# TM4C123GH6PM register map
Vendor: Texas Instruments; Series: TM4C; File version: 11073
CPU: CM4 r1p2, little endian, MPU, FPU, 3 interrupt priority bits
Registers are 32-bit, read-write, reset 0x1 unless marked. A register's access mark holds for its fields unless they carry their own. Offsets are from the block's base; [hi:lo] are bit positions; {n}, {i} and the like mark numbered series.

## UDMA — Register map for UDMA peripheral
Base 0x400FF000; register names take the prefix UDMA
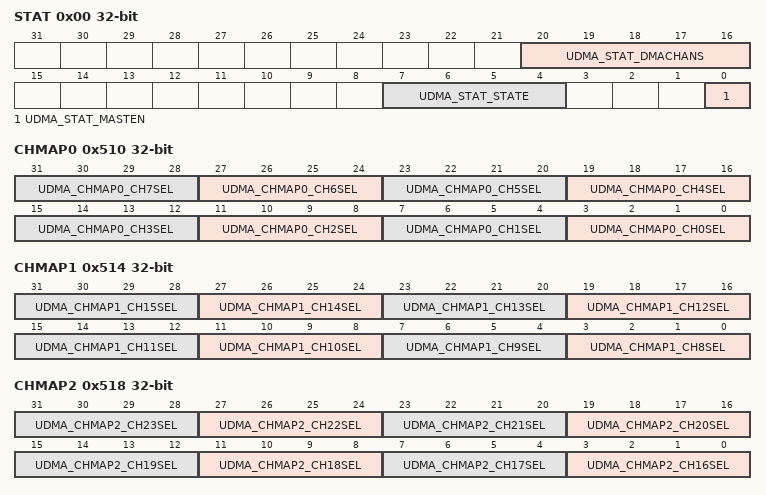
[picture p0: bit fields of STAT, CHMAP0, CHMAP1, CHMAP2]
0x00 STAT (reset mask 0x0) — DMA Status
  [20:16] UDMA_STAT_DMACHANS — Available uDMA Channels Minus 1
  [7:4] UDMA_STAT_STATE — Control State Machine Status
    0=UDMA_STAT_STATE_IDLE (Idle); 1=UDMA_STAT_STATE_RD_CTRL (Reading channel controller data); 2=UDMA_STAT_STATE_RD_SRCENDP (Reading source end pointer); 3=UDMA_STAT_STATE_RD_DSTENDP (Reading destination end pointer); 4=UDMA_STAT_STATE_RD_SRCDAT (Reading source data); 5=UDMA_STAT_STATE_WR_DSTDAT (Writing destination data); 6=UDMA_STAT_STATE_WAIT (Waiting for uDMA request to clear); 7=UDMA_STAT_STATE_WR_CTRL (Writing channel controller data); 8=UDMA_STAT_STATE_STALL (Stalled); 9=UDMA_STAT_STATE_DONE (Done); 10=UDMA_STAT_STATE_UNDEF (Undefined)
  [0] UDMA_STAT_MASTEN — Master Enable Status
0x04 CFG wo (reset mask 0x0) — DMA Configuration
  [0] UDMA_CFG_MASTEN — Controller Master Enable
0x08 CTLBASE (reset mask 0x0) — DMA Channel Control Base Pointer
  [31:10] UDMA_CTLBASE_ADDR — Channel Control Base Address
0x0C ALTBASE (reset mask 0x0) — DMA Alternate Channel Control Base Pointer
  [31:0] UDMA_ALTBASE_ADDR — Alternate Channel Address Pointer
0x10 WAITSTAT (reset mask 0x0) — DMA Channel Wait-on-Request Status
  [31:0] UDMA_WAITSTAT_WAITREQ — Channel [n] Wait Status
0x14 SWREQ wo (reset mask 0x0) — DMA Channel Software Request
  [31:0] UDMA_SWREQ — Channel [n] Software Request
0x18 USEBURSTSET (reset mask 0x0) — DMA Channel Useburst Set
  [31:0] UDMA_USEBURSTSET_SET — Channel [n] Useburst Set
0x1C USEBURSTCLR wo (reset mask 0x0) — DMA Channel Useburst Clear
  [31:0] UDMA_USEBURSTCLR_CLR — Channel [n] Useburst Clear
0x20 REQMASKSET (reset mask 0x0) — DMA Channel Request Mask Set
  [31:0] UDMA_REQMASKSET_SET — Channel [n] Request Mask Set
0x24 REQMASKCLR wo (reset mask 0x0) — DMA Channel Request Mask Clear
  [31:0] UDMA_REQMASKCLR_CLR — Channel [n] Request Mask Clear
0x28 ENASET (reset mask 0x0) — DMA Channel Enable Set
  [31:0] UDMA_ENASET_SET — Channel [n] Enable Set
0x2C ENACLR wo (reset mask 0x0) — DMA Channel Enable Clear
  [31:0] UDMA_ENACLR_CLR — Clear Channel [n] Enable Clear
0x30 ALTSET (reset mask 0x0) — DMA Channel Primary Alternate Set
  [31:0] UDMA_ALTSET_SET — Channel [n] Alternate Set
0x34 ALTCLR wo (reset mask 0x0) — DMA Channel Primary Alternate Clear
  [31:0] UDMA_ALTCLR_CLR — Channel [n] Alternate Clear
0x38 PRIOSET (reset mask 0x0) — DMA Channel Priority Set
  [31:0] UDMA_PRIOSET_SET — Channel [n] Priority Set
0x3C PRIOCLR wo (reset mask 0x0) — DMA Channel Priority Clear
  [31:0] UDMA_PRIOCLR_CLR — Channel [n] Priority Clear
0x4C ERRCLR (reset mask 0x0) — DMA Bus Error Clear
  [0] UDMA_ERRCLR_ERRCLR — uDMA Bus Error Status
0x500 CHASGN (reset mask 0x0) — DMA Channel Assignment
  [31:0] UDMA_CHASGN — Channel [n] Assignment Select
    0=UDMA_CHASGN_PRIMARY (Use the primary channel assignment); 1=UDMA_CHASGN_SECONDARY (Use the secondary channel assignment)
0x504 CHIS (reset mask 0x0) — DMA Channel Interrupt Status
  [31:0] UDMA_CHIS — Channel [n] Interrupt Status
0x510 CHMAP0 (reset mask 0x0) — DMA Channel Map Select 0
  [4n+3:4n] UDMA_CHMAP0_CH{n}SEL (n=0..7) — uDMA Channel {n} Source Select
0x514 CHMAP1 (reset mask 0x0) — DMA Channel Map Select 1
  [4n-29:4n-32] UDMA_CHMAP1_CH{n}SEL (n=8..15) — uDMA Channel {n} Source Select
0x518 CHMAP2 (reset mask 0x0) — DMA Channel Map Select 2
  [4n-61:4n-64] UDMA_CHMAP2_CH{n}SEL (n=16..23) — uDMA Channel {n} Source Select
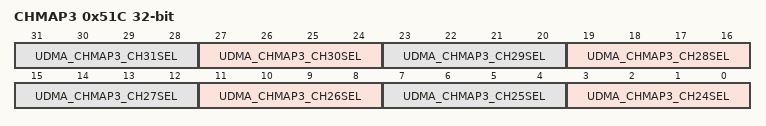
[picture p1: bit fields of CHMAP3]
0x51C CHMAP3 (reset mask 0x0) — DMA Channel Map Select 3
  [4n-93:4n-96] UDMA_CHMAP3_CH{n}SEL (n=24..31) — uDMA Channel {n} Source Select
